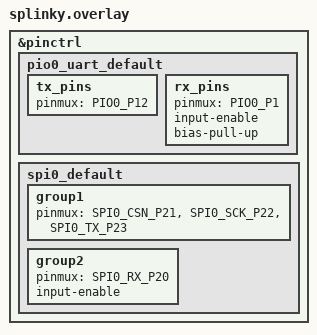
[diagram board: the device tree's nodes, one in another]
&pinctrl {
    pio0_uart_default: pio0_uart_default {
        tx_pins {
            pinmux = <PIO0_P12>;
            };
        rx_pins {
            pinmux = <PIO0_P1>;
            /* enable input on pin 1 */
            input-enable;
            bias-pull-up;
        };
    };

    spi0_default: spi0_default {
        group1 {
            pinmux = <SPI0_CSN_P21>, <SPI0_SCK_P22>, <SPI0_TX_P23>;
        };
        group2 {
            pinmux = <SPI0_RX_P20>;
            input-enable;
        };
    };
};
